# Arm Cortex-A53 register map
File version: 1.0
Registers are 32-bit, access not given, no defined reset value unless marked. A register's access mark holds for its fields unless they carry their own. Offsets are from the block's base; lines under a group give offsets from that group; [hi:lo] are bit positions; {n}, {i} and the like mark numbered series; 'fields as' and 'values as' point back to an identical list; <NAME> marks a mode.

## Memory map
0x00000000 PL011 size 0x1000

## PL011
Base 0x00000000
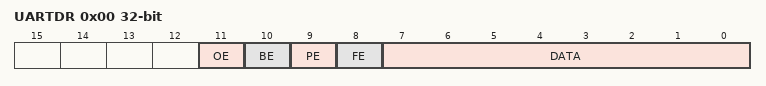
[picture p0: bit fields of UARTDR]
0x00 UARTDR — Data Register
  [11] OE, [10] BE, [9] PE, [8] FE, [7:0] DATA
